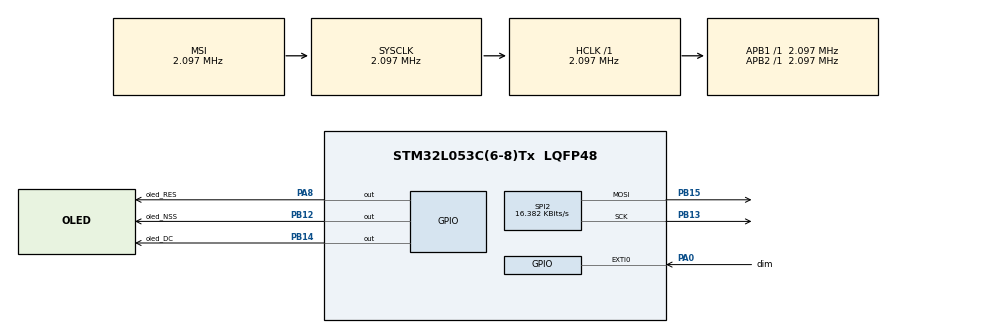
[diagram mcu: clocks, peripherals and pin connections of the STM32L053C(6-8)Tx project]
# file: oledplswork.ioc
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Mcu.Family=STM32L0
Mcu.Name=STM32L053C(6-8)Tx
Mcu.Package=LQFP48
NVIC.EXTI0_1_IRQn=true\:0\:0\:false\:false\:true\:true\:true
NVIC.TIM2_IRQn=true\:0\:0\:false\:false\:true\:true\:true
PA0.GPIO_Label=dim
PA0.GPIO_ModeDefaultEXTI=GPIO_MODE_IT_FALLING
PA0.Signal=GPXTI0
PA8.GPIO_Label=oled_RES
PA8.GPIO_Speed=GPIO_SPEED_FREQ_LOW
PA8.Signal=GPIO_Output
PB12.GPIO_Label=oled_NSS
PB12.Signal=GPIO_Output
PB13.Mode=TX_Only_Simplex_Unidirect_Master
PB13.Signal=SPI2_SCK
PB14.GPIO_Label=oled_DC
PB14.Signal=GPIO_Output
PB15.Mode=TX_Only_Simplex_Unidirect_Master
PB15.Signal=SPI2_MOSI
ProjectManager.HeapSize=0x200
ProjectManager.StackSize=0x400
ProjectManager.TargetToolchain=TrueSTUDIO
RCC.AHBFreq_Value=2097000
RCC.APB1Freq_Value=2097000
RCC.APB1TimFreq_Value=2097000
RCC.APB2Freq_Value=2097000
RCC.APB2TimFreq_Value=2097000
RCC.HCLKFreq_Value=2097000
RCC.HSE_VALUE=8000000
RCC.HSI16_VALUE=16000000
RCC.HSI48_VALUE=48000000
RCC.HSI_VALUE=16000000
RCC.LSE_VALUE=32768
RCC.MSI_VALUE=2097000
RCC.PLLMUL=RCC_PLLMUL_4
RCC.SYSCLKFreq_VALUE=2097000
RCC.VCOOutputFreq_Value=64000000
SPI2.BaudRatePrescaler=SPI_BAUDRATEPRESCALER_128
SPI2.CalculateBaudRate=16.382 KBits/s
SPI2.Direction=SPI_DIRECTION_2LINES
SPI2.Mode=SPI_MODE_MASTER
SPI2.VirtualType=VM_MASTER
TIM2.AutoReloadPreload=TIM_AUTORELOAD_PRELOAD_DISABLE
TIM2.ClockDivision=TIM_CLOCKDIVISION_DIV1
TIM2.Period=100
TIM2.Prescaler=20096
VP_TIM2_VS_ClockSourceINT.Mode=Internal
board=custom

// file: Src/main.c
/* USER CODE BEGIN Header */
/**
  ******************************************************************************
  * @file           : main.c
  * @brief          : Main program body
  ******************************************************************************
  * @attention
  *
  * <h2><center>&copy; Copyright (c) 2020 STMicroelectronics.
  * All rights reserved.</center></h2>
  *
  * This software component is licensed by ST under BSD 3-Clause license,
  * the "License"; You may not use this file except in compliance with the
  * License. You may obtain a copy of the License at:
  *                        opensource.org/licenses/BSD-3-Clause
  *
  ******************************************************************************
  */
/* USER CODE END Header */

#include "main.h"

/* USER CODE BEGIN Includes */
#include "oled.h"
/* USER CODE END Includes */

SPI_HandleTypeDef hspi2;

TIM_HandleTypeDef htim2;

void SystemClock_Config(void);
static void MX_GPIO_Init(void);
static void MX_SPI2_Init(void);
static void MX_TIM2_Init(void);

/* USER CODE BEGIN 0 */

uint8_t contrastLow[]={0x81, 0x0F};
uint8_t contrastHigh[]={0x81, 0xFF};

uint8_t isDim = 0;
/* USER CODE END 0 */

int main(void)
{

  /* MCU Configuration--------------------------------------------------------*/

  /* Reset of all peripherals, Initializes the Flash interface and the Systick. */
  HAL_Init();

  /* Configure the system clock */
  SystemClock_Config();

  /* Initialize all configured peripherals */
  MX_GPIO_Init();
  MX_SPI2_Init();
  MX_TIM2_Init();
  /* USER CODE BEGIN 2 */

  turnOnScreen();
  HAL_TIM_Base_Start_IT(&htim2);
  /* USER CODE END 2 */

  /* Infinite loop */
  while (1)
  {

  }
}

void SystemClock_Config(void)
{
  RCC_OscInitTypeDef RCC_OscInitStruct = {0};
  RCC_ClkInitTypeDef RCC_ClkInitStruct = {0};

  /** Configure the main internal regulator output voltage
  */
  __HAL_PWR_VOLTAGESCALING_CONFIG(PWR_REGULATOR_VOLTAGE_SCALE1);
  /** Initializes the CPU, AHB and APB busses clocks
  */
  RCC_OscInitStruct.OscillatorType = RCC_OSCILLATORTYPE_MSI;
  RCC_OscInitStruct.MSIState = RCC_MSI_ON;
  RCC_OscInitStruct.MSICalibrationValue = 0;
  RCC_OscInitStruct.MSIClockRange = RCC_MSIRANGE_5;
  RCC_OscInitStruct.PLL.PLLState = RCC_PLL_NONE;
  if (HAL_RCC_OscConfig(&RCC_OscInitStruct) != HAL_OK)
  {
    Error_Handler();
  }
  /** Initializes the CPU, AHB and APB busses clocks
  */
  RCC_ClkInitStruct.ClockType = RCC_CLOCKTYPE_HCLK|RCC_CLOCKTYPE_SYSCLK
                              |RCC_CLOCKTYPE_PCLK1|RCC_CLOCKTYPE_PCLK2;
  RCC_ClkInitStruct.SYSCLKSource = RCC_SYSCLKSOURCE_MSI;
  RCC_ClkInitStruct.AHBCLKDivider = RCC_SYSCLK_DIV1;
  RCC_ClkInitStruct.APB1CLKDivider = RCC_HCLK_DIV1;
  RCC_ClkInitStruct.APB2CLKDivider = RCC_HCLK_DIV1;

  if (HAL_RCC_ClockConfig(&RCC_ClkInitStruct, FLASH_LATENCY_0) != HAL_OK)
  {
    Error_Handler();
  }
}

static void MX_SPI2_Init(void)
{

  /* SPI2 parameter configuration*/
  hspi2.Instance = SPI2;
  hspi2.Init.Mode = SPI_MODE_MASTER;
  hspi2.Init.Direction = SPI_DIRECTION_2LINES;
  hspi2.Init.DataSize = SPI_DATASIZE_8BIT;
  hspi2.Init.CLKPolarity = SPI_POLARITY_LOW;
  hspi2.Init.CLKPhase = SPI_PHASE_1EDGE;
  hspi2.Init.NSS = SPI_NSS_SOFT;
  hspi2.Init.BaudRatePrescaler = SPI_BAUDRATEPRESCALER_128;
  hspi2.Init.FirstBit = SPI_FIRSTBIT_MSB;
  hspi2.Init.TIMode = SPI_TIMODE_DISABLE;
  hspi2.Init.CRCCalculation = SPI_CRCCALCULATION_DISABLE;
  hspi2.Init.CRCPolynomial = 7;
  if (HAL_SPI_Init(&hspi2) != HAL_OK)
  {
    Error_Handler();
  }

}

static void MX_TIM2_Init(void)
{

  TIM_ClockConfigTypeDef sClockSourceConfig = {0};
  TIM_MasterConfigTypeDef sMasterConfig = {0};

  htim2.Instance = TIM2;
  htim2.Init.Prescaler = 20096;
  htim2.Init.CounterMode = TIM_COUNTERMODE_UP;
  htim2.Init.Period = 100;
  htim2.Init.ClockDivision = TIM_CLOCKDIVISION_DIV1;
  htim2.Init.AutoReloadPreload = TIM_AUTORELOAD_PRELOAD_DISABLE;
  if (HAL_TIM_Base_Init(&htim2) != HAL_OK)
  {
    Error_Handler();
  }
  sClockSourceConfig.ClockSource = TIM_CLOCKSOURCE_INTERNAL;
  if (HAL_TIM_ConfigClockSource(&htim2, &sClockSourceConfig) != HAL_OK)
  {
    Error_Handler();
  }
  sMasterConfig.MasterOutputTrigger = TIM_TRGO_RESET;
  sMasterConfig.MasterSlaveMode = TIM_MASTERSLAVEMODE_DISABLE;
  if (HAL_TIMEx_MasterConfigSynchronization(&htim2, &sMasterConfig) != HAL_OK)
  {
    Error_Handler();
  }

}

static void MX_GPIO_Init(void)
{
  GPIO_InitTypeDef GPIO_InitStruct = {0};

  /* GPIO Ports Clock Enable */
  __HAL_RCC_GPIOA_CLK_ENABLE();
  __HAL_RCC_GPIOB_CLK_ENABLE();

  /*Configure GPIO pin Output Level */
  HAL_GPIO_WritePin(GPIOB, oled_NSS_Pin|oled_DC_Pin, GPIO_PIN_RESET);

  /*Configure GPIO pin Output Level */
  HAL_GPIO_WritePin(oled_RES_GPIO_Port, oled_RES_Pin, GPIO_PIN_RESET);

  /*Configure GPIO pin : dim_Pin */
  GPIO_InitStruct.Pin = dim_Pin;
  GPIO_InitStruct.Mode = GPIO_MODE_IT_FALLING;
  GPIO_InitStruct.Pull = GPIO_NOPULL;
  HAL_GPIO_Init(dim_GPIO_Port, &GPIO_InitStruct);

  /*Configure GPIO pins : oled_NSS_Pin oled_DC_Pin */
  GPIO_InitStruct.Pin = oled_NSS_Pin|oled_DC_Pin;
  GPIO_InitStruct.Mode = GPIO_MODE_OUTPUT_PP;
  GPIO_InitStruct.Pull = GPIO_NOPULL;
  GPIO_InitStruct.Speed = GPIO_SPEED_FREQ_LOW;
  HAL_GPIO_Init(GPIOB, &GPIO_InitStruct);

  /*Configure GPIO pin : oled_RES_Pin */
  GPIO_InitStruct.Pin = oled_RES_Pin;
  GPIO_InitStruct.Mode = GPIO_MODE_OUTPUT_PP;
  GPIO_InitStruct.Pull = GPIO_NOPULL;
  GPIO_InitStruct.Speed = GPIO_SPEED_FREQ_LOW;
  HAL_GPIO_Init(oled_RES_GPIO_Port, &GPIO_InitStruct);

  /* EXTI interrupt init*/
  HAL_NVIC_SetPriority(EXTI0_1_IRQn, 0, 0);
  HAL_NVIC_EnableIRQ(EXTI0_1_IRQn);

}

/* USER CODE BEGIN 4 */
void HAL_GPIO_EXTI_Callback(uint16_t GPIO_Pin){
	if(isDim){

			sendCMD(contrastHigh, (uint16_t)sizeof(contrastHigh));
			isDim = 0;
		}
	else{

			 sendCMD(contrastLow, (uint16_t)sizeof(contrastLow));
			 isDim=1;
		}
}

/* USER CODE END 4 */

void Error_Handler(void)
{
}

/************************ (C) COPYRIGHT STMicroelectronics *****END OF FILE****/
